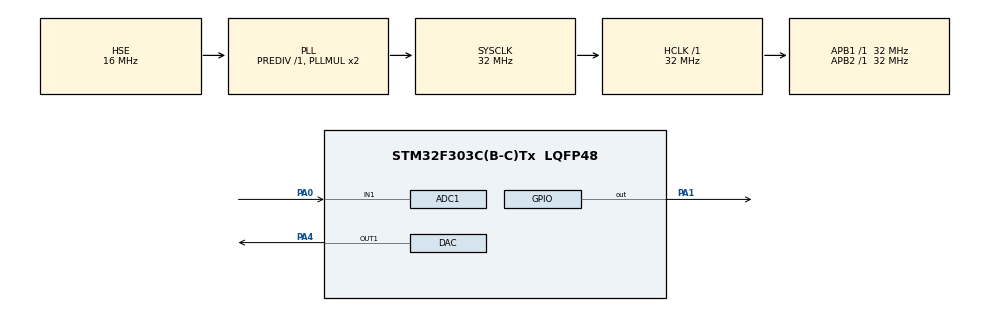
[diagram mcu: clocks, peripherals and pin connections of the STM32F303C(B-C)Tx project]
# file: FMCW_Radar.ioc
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ADC1.Channel-0\#ChannelRegularConversion=ADC_CHANNEL_1
ADC1.ContinuousConvMode=DISABLE
ADC1.DMAContinuousRequests=ENABLE
ADC1.ExternalTrigConv=ADC_EXTERNALTRIGCONV_T2_TRGO
ADC1.NbrOfConversionFlag=1
ADC1.Offset-0\#ChannelRegularConversion=0
ADC1.OffsetNumber-0\#ChannelRegularConversion=ADC_OFFSET_NONE
ADC1.Rank-0\#ChannelRegularConversion=1
ADC1.SamplingTime-0\#ChannelRegularConversion=ADC_SAMPLETIME_1CYCLE_5
ADC1.SamplingTimeOPAMP-0\#ChannelRegularConversion=ADC_SAMPLETIME_19CYCLES_5
ADC1.master=1
DAC.DAC_Trigger=DAC_TRIGGER_T2_TRGO
Dma.ADC1.1.Direction=DMA_PERIPH_TO_MEMORY
Dma.ADC1.1.Instance=DMA1_Channel1
Dma.ADC1.1.MemDataAlignment=DMA_MDATAALIGN_HALFWORD
Dma.ADC1.1.MemInc=DMA_MINC_ENABLE
Dma.ADC1.1.Mode=DMA_CIRCULAR
Dma.ADC1.1.PeriphDataAlignment=DMA_PDATAALIGN_HALFWORD
Dma.ADC1.1.PeriphInc=DMA_PINC_DISABLE
Dma.ADC1.1.Priority=DMA_PRIORITY_LOW
Dma.DAC_CH1.0.Direction=DMA_MEMORY_TO_PERIPH
Dma.DAC_CH1.0.Instance=DMA1_Channel3
Dma.DAC_CH1.0.MemDataAlignment=DMA_MDATAALIGN_WORD
Dma.DAC_CH1.0.MemInc=DMA_MINC_ENABLE
Dma.DAC_CH1.0.Mode=DMA_CIRCULAR
Dma.DAC_CH1.0.PeriphDataAlignment=DMA_PDATAALIGN_WORD
Dma.DAC_CH1.0.PeriphInc=DMA_PINC_DISABLE
Dma.DAC_CH1.0.Priority=DMA_PRIORITY_LOW
Dma.Request0=DAC_CH1
Dma.Request1=ADC1
Mcu.Family=STM32F3
Mcu.Name=STM32F303C(B-C)Tx
Mcu.Package=LQFP48
NVIC.DMA1_Channel1_IRQn=true\:0\:0\:false\:false\:true\:false\:true\:true
NVIC.DMA1_Channel3_IRQn=true\:0\:0\:false\:false\:true\:false\:true\:true
NVIC.PriorityGroup=NVIC_PRIORITYGROUP_4
PA0.Mode=IN1-Single-Ended
PA0.Signal=ADC1_IN1
PA1.PinState=GPIO_PIN_SET
PA1.Signal=GPIO_Output
PA4.Signal=COMP_DAC1_group
PF0-OSC_IN.Mode=HSE-External-Oscillator
PF0-OSC_IN.Signal=RCC_OSC_IN
PF1-OSC_OUT.Mode=HSE-External-Oscillator
PF1-OSC_OUT.Signal=RCC_OSC_OUT
ProjectManager.HeapSize=0x200
ProjectManager.StackSize=0x400
ProjectManager.TargetToolchain=STM32CubeIDE
RCC.AHBFreq_Value=32000000
RCC.APB1Freq_Value=32000000
RCC.APB1TimFreq_Value=32000000
RCC.APB2Freq_Value=32000000
RCC.APB2TimFreq_Value=32000000
RCC.CortexFreq_Value=32000000
RCC.HCLKFreq_Value=32000000
RCC.HSE_VALUE=16000000
RCC.HSI_VALUE=8000000
RCC.LSE_VALUE=32768
RCC.PLLSourceVirtual=RCC_PLLSOURCE_HSE
RCC.SYSCLKFreq_VALUE=32000000
RCC.SYSCLKSourceVirtual=RCC_SYSCLKSOURCE_PLLCLK
RCC.USBFreq_Value=32000000
SH.COMP_DAC1_group.0=DAC_OUT1,DAC_OUT1
TIM2.AutoReloadPreload=TIM_AUTORELOAD_PRELOAD_DISABLE
TIM2.Period=624
TIM2.Prescaler=1
TIM2.TIM_MasterOutputTrigger=TIM_TRGO_UPDATE
VP_TIM2_VS_ClockSourceINT.Mode=Internal
board=custom

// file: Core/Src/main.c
/* USER CODE BEGIN Header */
/**
  ******************************************************************************
  * @file           : main.c
  * @brief          : Main program body
  ******************************************************************************
  * @attention
  *
  * Copyright (c) 2025 STMicroelectronics.
  * All rights reserved.
  *
  * This software is licensed under terms that can be found in the LICENSE file
  * in the root directory of this software component.
  * If no LICENSE file comes with this software, it is provided AS-IS.
  *
  ******************************************************************************
  */
/* USER CODE END Header */
#include "main.h"

/* USER CODE BEGIN Includes */
#include "stm32f3xx_hal_dac.h"
#include "stm32f3xx_hal_adc_ex.h"
#include <stdio.h>
#include <string.h>
/* USER CODE END Includes */

ADC_HandleTypeDef hadc1;
DMA_HandleTypeDef hdma_adc1;

DAC_HandleTypeDef hdac;
DMA_HandleTypeDef hdma_dac_ch1;

TIM_HandleTypeDef htim2;

/* USER CODE BEGIN PV */
static const uint32_t Wave_LUT[DMA_BUF_SIZE] = {
     1117,  1120,  1124,  1127,  1131,  1134,  1138,  1141,  1145,  1148,  1152,  1155,  1159,  1162,  1166,  1169,
     1173,  1176,  1180,  1183,  1187,  1190,  1194,  1198,  1201,  1205,  1208,  1212,  1215,  1219,  1222,  1226,
     1230,  1233,  1237,  1240,  1244,  1247,  1251,  1255,  1258,  1262,  1265,  1269,  1273,  1276,  1280,  1284,
     1287,  1291,  1294,  1298,  1302,  1305,  1309,  1313,  1316,  1320,  1324,  1327,  1331,  1335,  1338,  1342,
     1346,  1349,  1353,  1357,  1361,  1364,  1368,  1372,  1375,  1379,  1383,  1387,  1390,  1394,  1398,  1402,
     1405,  1409,  1413,  1417,  1420,  1424,  1428,  1432,  1436,  1439,  1443,  1447,  1451,  1455,  1458,  1462,
     1466,  1470,  1474,  1478,  1481,  1485,  1489,  1493,  1497,  1501,  1505,  1509,  1512,  1516,  1520,  1524,
     1528,  1532,  1536,  1540,  1544,  1548,  1552,  1556,  1560,  1563,  1567,  1571,  1575,  1579,  1583,  1587,
     1591,  1595,  1599,  1603,  1607,  1612,  1616,  1620,  1624,  1628,  1632,  1636,  1640,  1644,  1648,  1652,
     1656,  1660,  1665,  1669,  1673,  1677,  1681,  1685,  1689,  1694,  1698,  1702,  1706,  1710,  1715,  1719,
     1723,  1727,  1731,  1736,  1740,  1744,  1748,  1753,  1757,  1761,  1766,  1770,  1774,  1779,  1783,  1787,
     1792,  1796,  1800,  1805,  1809,  1814,  1818,  1822,  1827,  1831,  1836,  1840,  1845,  1849,  1854,  1858,
     1863,  1867,  1872,  1876,  1881,  1885,  1890,  1894,  1899,  1904,  1908,  1913,  1917,  1922,  1927,  1931,
     1936,  1941,  1945,  1950,  1955,  1960,  1964,  1969,  1974,  1979,  1983,  1988,  1993,  1998,  2003,  2008,
     2013,  2017,  2022,  2027,  2032,  2037,  2042,  2047,  2052,  2057,  2062,  2067,  2072,  2077,  2082,  2088,
     2093,  2098,  2103,  2108,  2113,  2118,  2124,  2129,  2134,  2140,  2145,  2150,  2155,  2161,  2166,  2172
};
/* USER CODE END PV */

void SystemClock_Config(void);
static void MX_GPIO_Init(void);
static void MX_DMA_Init(void);
static void MX_DAC_Init(void);
static void MX_TIM2_Init(void);
static void MX_ADC1_Init(void);

/* USER CODE BEGIN 0 */

// This Function Provides Delay In Microseconds Using DWT
// Source: https://deepbluembedded.com/stm32-delay-microsecond-millisecond-utility-dwt-delay-timer-delay/
uint32_t DWT_Delay_Init(void)
{
    /* Disable TRC */
    CoreDebug->DEMCR &= ~CoreDebug_DEMCR_TRCENA_Msk; // ~0x01000000;
    /* Enable TRC */
    CoreDebug->DEMCR |=  CoreDebug_DEMCR_TRCENA_Msk; // 0x01000000;

    /* Disable clock cycle counter */
    DWT->CTRL &= ~DWT_CTRL_CYCCNTENA_Msk; //~0x00000001;
    /* Enable  clock cycle counter */
    DWT->CTRL |=  DWT_CTRL_CYCCNTENA_Msk; //0x00000001;

    /* Reset the clock cycle counter value */
    DWT->CYCCNT = 0;

    /* 3 NO OPERATION instructions */
    __ASM volatile ("NOP");
    __ASM volatile ("NOP");
    __ASM volatile ("NOP");

    /* Check if clock cycle counter has started */
    if(DWT->CYCCNT)
    {
       return 0; /*clock cycle counter started*/
    }
    else
    {
      return 1; /*clock cycle counter not started*/
    }
}

__STATIC_INLINE void DWT_Delay_us(volatile uint32_t au32_microseconds)
{
  uint32_t au32_initial_ticks = DWT->CYCCNT;
  uint32_t au32_ticks = (HAL_RCC_GetHCLKFreq() / 1000000);
  au32_microseconds *= au32_ticks;
  while ((DWT->CYCCNT - au32_initial_ticks) < au32_microseconds-au32_ticks);
}
/* USER CODE END 0 */

int main(void)
{

  /* MCU Configuration--------------------------------------------------------*/

  /* Reset of all peripherals, Initializes the Flash interface and the Systick. */
  HAL_Init();

  /* Configure the system clock */
  SystemClock_Config();

  /* Initialize all configured peripherals */
  MX_GPIO_Init();
  MX_DMA_Init();
  MX_DAC_Init();
  MX_TIM2_Init();
  MX_ADC1_Init();
  /* USER CODE BEGIN 2 */
  HAL_GPIO_WritePin (GPIOA, GPIO_PIN_1, GPIO_PIN_SET);
  HAL_ADCEx_Calibration_Start(&hadc1, ADC_SINGLE_ENDED);
  if (HAL_DAC_Start_DMA(&hdac, DAC_CHANNEL_1, Wave_LUT, DMA_BUF_SIZE, DAC_ALIGN_12B_R) != HAL_OK) Error_Handler();
  if (HAL_ADC_Start_DMA(&hadc1, (uint32_t*)adc_buf, DMA_BUF_SIZE) != HAL_OK) Error_Handler();
  if (HAL_TIM_Base_Start(&htim2) != HAL_OK) Error_Handler();

  /* USER CODE END 2 */

  /* Infinite loop */
  /* USER CODE BEGIN WHILE */
  while (1)
  {
	if (isAdcTransferComplete) {
		char outputString[4096] = { ' ' };
		char value[8];
		for (int i = 0; i < DMA_BUF_SIZE; i++) {
			snprintf(value, 8, "%d, ", adc_complete_acquisition[i]);
			memcpy(&(outputString[8 * i]), value, strlen(value));
			// printf("%d, ", adc_complete_acquisition[i]);
		}
		// printf("\n");
		isAdcTransferComplete = 0;
	}

	HAL_Delay(1);
    /* USER CODE END WHILE */

  }
}

void SystemClock_Config(void)
{
  RCC_OscInitTypeDef RCC_OscInitStruct = {0};
  RCC_ClkInitTypeDef RCC_ClkInitStruct = {0};
  RCC_PeriphCLKInitTypeDef PeriphClkInit = {0};

  /** Initializes the RCC Oscillators according to the specified parameters
  * in the RCC_OscInitTypeDef structure.
  */
  RCC_OscInitStruct.OscillatorType = RCC_OSCILLATORTYPE_HSE;
  RCC_OscInitStruct.HSEState = RCC_HSE_ON;
  RCC_OscInitStruct.HSEPredivValue = RCC_HSE_PREDIV_DIV1;
  RCC_OscInitStruct.HSIState = RCC_HSI_ON;
  RCC_OscInitStruct.PLL.PLLState = RCC_PLL_ON;
  RCC_OscInitStruct.PLL.PLLSource = RCC_PLLSOURCE_HSE;
  RCC_OscInitStruct.PLL.PLLMUL = RCC_PLL_MUL2;
  if (HAL_RCC_OscConfig(&RCC_OscInitStruct) != HAL_OK)
  {
    Error_Handler();
  }

  /** Initializes the CPU, AHB and APB buses clocks
  */
  RCC_ClkInitStruct.ClockType = RCC_CLOCKTYPE_HCLK|RCC_CLOCKTYPE_SYSCLK
                              |RCC_CLOCKTYPE_PCLK1|RCC_CLOCKTYPE_PCLK2;
  RCC_ClkInitStruct.SYSCLKSource = RCC_SYSCLKSOURCE_PLLCLK;
  RCC_ClkInitStruct.AHBCLKDivider = RCC_SYSCLK_DIV1;
  RCC_ClkInitStruct.APB1CLKDivider = RCC_HCLK_DIV1;
  RCC_ClkInitStruct.APB2CLKDivider = RCC_HCLK_DIV1;

  if (HAL_RCC_ClockConfig(&RCC_ClkInitStruct, FLASH_LATENCY_1) != HAL_OK)
  {
    Error_Handler();
  }
  PeriphClkInit.PeriphClockSelection = RCC_PERIPHCLK_ADC12;
  PeriphClkInit.Adc12ClockSelection = RCC_ADC12PLLCLK_DIV1;
  if (HAL_RCCEx_PeriphCLKConfig(&PeriphClkInit) != HAL_OK)
  {
    Error_Handler();
  }
}

static void MX_ADC1_Init(void)
{

  ADC_MultiModeTypeDef multimode = {0};
  ADC_ChannelConfTypeDef sConfig = {0};

  /** Common config
  */
  hadc1.Instance = ADC1;
  hadc1.Init.ClockPrescaler = ADC_CLOCK_ASYNC_DIV1;
  hadc1.Init.Resolution = ADC_RESOLUTION_12B;
  hadc1.Init.ScanConvMode = ADC_SCAN_DISABLE;
  hadc1.Init.ContinuousConvMode = DISABLE;
  hadc1.Init.DiscontinuousConvMode = DISABLE;
  hadc1.Init.ExternalTrigConvEdge = ADC_EXTERNALTRIGCONVEDGE_RISING;
  hadc1.Init.ExternalTrigConv = ADC_EXTERNALTRIGCONV_T2_TRGO;
  hadc1.Init.DataAlign = ADC_DATAALIGN_RIGHT;
  hadc1.Init.NbrOfConversion = 1;
  hadc1.Init.DMAContinuousRequests = ENABLE;
  hadc1.Init.EOCSelection = ADC_EOC_SINGLE_CONV;
  hadc1.Init.LowPowerAutoWait = DISABLE;
  hadc1.Init.Overrun = ADC_OVR_DATA_OVERWRITTEN;
  if (HAL_ADC_Init(&hadc1) != HAL_OK)
  {
    Error_Handler();
  }

  /** Configure the ADC multi-mode
  */
  multimode.Mode = ADC_MODE_INDEPENDENT;
  if (HAL_ADCEx_MultiModeConfigChannel(&hadc1, &multimode) != HAL_OK)
  {
    Error_Handler();
  }

  /** Configure Regular Channel
  */
  sConfig.Channel = ADC_CHANNEL_1;
  sConfig.Rank = ADC_REGULAR_RANK_1;
  sConfig.SingleDiff = ADC_SINGLE_ENDED;
  sConfig.SamplingTime = ADC_SAMPLETIME_61CYCLES_5;
  sConfig.OffsetNumber = ADC_OFFSET_NONE;
  sConfig.Offset = 0;
  if (HAL_ADC_ConfigChannel(&hadc1, &sConfig) != HAL_OK)
  {
    Error_Handler();
  }

}

static void MX_DAC_Init(void)
{

  DAC_ChannelConfTypeDef sConfig = {0};

  /** DAC Initialization
  */
  hdac.Instance = DAC;
  if (HAL_DAC_Init(&hdac) != HAL_OK)
  {
    Error_Handler();
  }

  /** DAC channel OUT1 config
  */
  sConfig.DAC_Trigger = DAC_TRIGGER_T2_TRGO;
  sConfig.DAC_OutputBuffer = DAC_OUTPUTBUFFER_ENABLE;
  if (HAL_DAC_ConfigChannel(&hdac, &sConfig, DAC_CHANNEL_1) != HAL_OK)
  {
    Error_Handler();
  }

}

static void MX_TIM2_Init(void)
{

  TIM_ClockConfigTypeDef sClockSourceConfig = {0};
  TIM_MasterConfigTypeDef sMasterConfig = {0};

  htim2.Instance = TIM2;
  htim2.Init.Prescaler = 0;
  htim2.Init.CounterMode = TIM_COUNTERMODE_UP;
  htim2.Init.Period = 624;
  htim2.Init.ClockDivision = TIM_CLOCKDIVISION_DIV1;
  htim2.Init.AutoReloadPreload = TIM_AUTORELOAD_PRELOAD_DISABLE;
  if (HAL_TIM_Base_Init(&htim2) != HAL_OK)
  {
    Error_Handler();
  }
  sClockSourceConfig.ClockSource = TIM_CLOCKSOURCE_INTERNAL;
  if (HAL_TIM_ConfigClockSource(&htim2, &sClockSourceConfig) != HAL_OK)
  {
    Error_Handler();
  }
  sMasterConfig.MasterOutputTrigger = TIM_TRGO_UPDATE;
  sMasterConfig.MasterSlaveMode = TIM_MASTERSLAVEMODE_DISABLE;
  if (HAL_TIMEx_MasterConfigSynchronization(&htim2, &sMasterConfig) != HAL_OK)
  {
    Error_Handler();
  }

}

static void MX_DMA_Init(void)
{

  /* DMA controller clock enable */
  __HAL_RCC_DMA1_CLK_ENABLE();

  /* DMA interrupt init */
  /* DMA1_Channel1_IRQn interrupt configuration */
  HAL_NVIC_SetPriority(DMA1_Channel1_IRQn, 0, 0);
  HAL_NVIC_EnableIRQ(DMA1_Channel1_IRQn);
  /* DMA1_Channel3_IRQn interrupt configuration */
  HAL_NVIC_SetPriority(DMA1_Channel3_IRQn, 0, 0);
  HAL_NVIC_EnableIRQ(DMA1_Channel3_IRQn);

}

static void MX_GPIO_Init(void)
{
  GPIO_InitTypeDef GPIO_InitStruct = {0};

  /* GPIO Ports Clock Enable */
  __HAL_RCC_GPIOF_CLK_ENABLE();
  __HAL_RCC_GPIOA_CLK_ENABLE();

  /*Configure GPIO pin Output Level */
  HAL_GPIO_WritePin(GPIOA, GPIO_PIN_1, GPIO_PIN_SET);

  /*Configure GPIO pin : PA1 */
  GPIO_InitStruct.Pin = GPIO_PIN_1;
  GPIO_InitStruct.Mode = GPIO_MODE_OUTPUT_PP;
  GPIO_InitStruct.Pull = GPIO_NOPULL;
  GPIO_InitStruct.Speed = GPIO_SPEED_FREQ_LOW;
  HAL_GPIO_Init(GPIOA, &GPIO_InitStruct);

}

void Error_Handler(void)
{
  __disable_irq();
  while (1)
  {
  }
}
